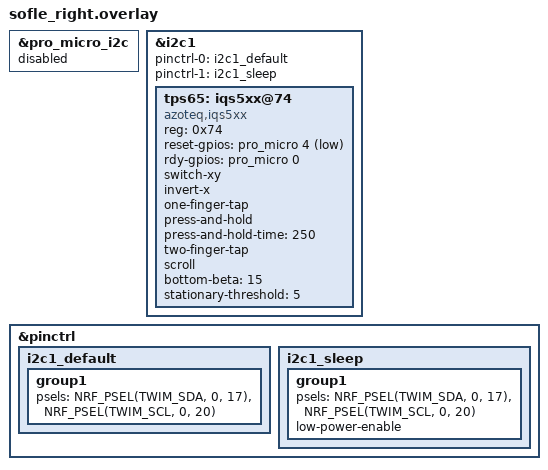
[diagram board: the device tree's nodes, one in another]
#include <dt-bindings/led/led.h>
#include "sofle.dtsi"

/* --- 1. CLEANUP: Disable Default I2C to avoid conflicts --- */
&pro_micro_i2c { status = "disabled"; };

/* --- 2. SETUP TRACKPAD on I2C1 (Just like Left Side) --- */
&i2c1 {
    status = "okay";
    
    /* Map Standard Sofle I2C Pins (SDA=17, SCL=20) */
    pinctrl-0 = <&i2c1_default>;
    pinctrl-1 = <&i2c1_sleep>;
    pinctrl-names = "default", "sleep";

    /* Local Trackpad (TPS65) */
    tps65: iqs5xx@74 {
        compatible = "azoteq,iqs5xx";
        status = "okay";
        reg = <0x74>;
        
        /* Pins for Right Side */
        reset-gpios = <&pro_micro 4 GPIO_ACTIVE_LOW>;
        rdy-gpios = <&pro_micro 0 GPIO_ACTIVE_HIGH>;

        /* --- 3. ROTATION SETTINGS (The "Old Way") --- */
        /* v0.3 doesn't support input-processors. We must set it here. */
        
        /* 90-degree rotation logic: Swap X/Y */
        switch-xy;
        
        /* Fix Direction: Uncomment these one by one if mouse moves wrong way */
        invert-x;
        /* invert-y; */

        /* Standard Settings */
        one-finger-tap;
        press-and-hold;
        press-and-hold-time = <250>;
        two-finger-tap;
        scroll;
        /* natural-scroll-x; */ /* Commented out as v0.3 might not support it */
        bottom-beta = <15>;
        stationary-threshold = <5>;
    };
};

/* --- 4. PIN DEFINITIONS (Required for i2c1) --- */
&pinctrl {
    i2c1_default: i2c1_default {
        group1 { psels = <NRF_PSEL(TWIM_SDA, 0, 17)>, <NRF_PSEL(TWIM_SCL, 0, 20)>; };
    };
    i2c1_sleep: i2c1_sleep {
        group1 { psels = <NRF_PSEL(TWIM_SDA, 0, 17)>, <NRF_PSEL(TWIM_SCL, 0, 20)>; low-power-enable; };
    };
};

/* --- 5. CLEANUP: Remove Future Features --- */
/*
   Deleted: zip_xy_transform
   Deleted: zip_scroll_transform
   Deleted: right_trackpad_split
   
   These do not exist in ZMK v0.3. 
   The system will handle the split input automatically.
*/
